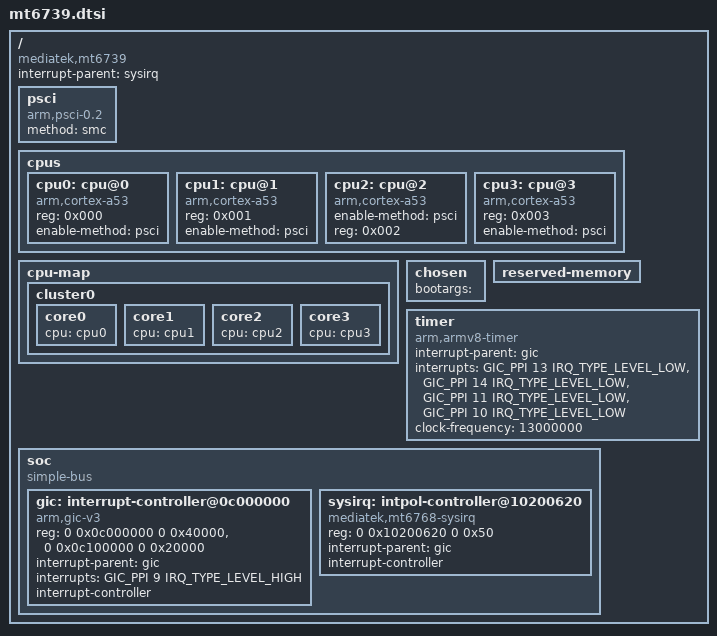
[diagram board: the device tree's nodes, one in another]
// SPDX-License-Identifier: GPL-2.0
/*
 * Copyright (c) 2024 Hoang Long
 */

#include <dt-bindings/interrupt-controller/irq.h>
#include <dt-bindings/interrupt-controller/arm-gic.h>

/ {
    compatible = "mediatek,mt6739";
    interrupt-parent = <&sysirq>;
    #address-cells = <2>;
    #size-cells = <2>;

    psci {
        compatible = "arm,psci-0.2";
        method = "smc";
    };

    cpus {
        #address-cells = <1>;
        #size-cells = <0>;

        cpu0: cpu@0 {
            device_type = "cpu";
            compatible = "arm,cortex-a53";
            reg = <0x000>;
            enable-method = "psci";
        };

        cpu1: cpu@1 {
            device_type = "cpu";
            compatible = "arm,cortex-a53";
            reg = <0x001>;
            enable-method = "psci";
        };

        cpu2: cpu@2 {
            device_type = "cpu";
            compatible = "arm,cortex-a53";
            enable-method = "psci";
            reg = <0x002>;
        };

        cpu3: cpu@3 {
            device_type = "cpu";
            compatible = "arm,cortex-a53";
            reg = <0x003>;
            enable-method = "psci";
        };
    };

    cpu-map {
        cluster0 {
            core0 {
                cpu = <&cpu0>;
            };
            core1 {
                cpu = <&cpu1>;
            };
            core2 {
                cpu = <&cpu2>;
            };
            core3 {
                cpu = <&cpu3>;
            };
        };
    };

	chosen {
		#address-cells = <2>;
		#size-cells = <2>;
		ranges;

0		/*
		 * NOTE: /chosen/bootargs has to exist even if unused or
		 * bootloader will be unhappy
		 */
		bootargs = "";
	};

	reserved-memory {
		#address-cells = <2>;
		#size-cells = <2>;
		ranges;

		/* TODO: add useful non-mblock nodes from downstream! */
	};

    timer {
        compatible = "arm,armv8-timer";
        interrupt-parent = <&gic>;
        interrupts = <GIC_PPI 13 IRQ_TYPE_LEVEL_LOW>,
                     <GIC_PPI 14 IRQ_TYPE_LEVEL_LOW>,
                     <GIC_PPI 11 IRQ_TYPE_LEVEL_LOW>,
                     <GIC_PPI 10 IRQ_TYPE_LEVEL_LOW>;
        clock-frequency = <13000000>;
    };

    soc {
        #address-cells = <2>;
        #size-cells = <2>;
        compatible = "simple-bus";
        ranges;

        gic: interrupt-controller@0c000000 {
            compatible = "arm,gic-v3";
            reg = <0 0x0c000000 0 0x40000>, /* GICD */
                  <0 0x0c100000 0 0x20000>; /* GICR */
            #interrupt-cells = <3>;
            interrupt-parent = <&gic>;
            interrupts = <GIC_PPI 9 IRQ_TYPE_LEVEL_HIGH>;
            interrupt-controller;
        };

        sysirq: intpol-controller@10200620 {
			compatible = "mediatek,mt6768-sysirq", "mediatek,mt6577-sysirq";
            reg = <0 0x10200620 0 0x50>;	/* INTPOL */
            #interrupt-cells = <3>;
            interrupt-parent = <&gic>;
            interrupt-controller;
        };
    };
};
